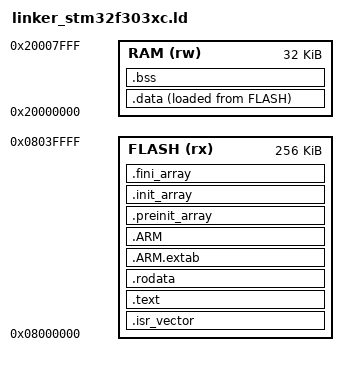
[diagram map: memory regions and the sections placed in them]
/**
 * linker_stm32f303xc.ld: Linker script for STM32F303xC (256K flash, 32K RAM).
 *
 * This is free software: you can redistribute it and/or modify
 * it under the terms of the GNU General Public License as published by
 * the Free Software Foundation, either version 3 of the License, or
 * (at your option) any later version.
 */

ENTRY(Reset_Handler)

MEMORY
{
    FLASH  (rx)  : ORIGIN = 0x08000000, LENGTH = 256K
    RAM    (rw)  : ORIGIN = 0x20000000, LENGTH = 32K
}

SECTIONS
{
    .isr_vector :
    {
        . = ALIGN(4);
        KEEP(*(.isr_vector))
        . = ALIGN(4);
    } > FLASH

    .text :
    {
        . = ALIGN(4);
        *(.text .text.*)
        *(.glue_7)
        *(.glue_7t)
        *(.gnu.linkonce.t.*)
        . = ALIGN(4);

        KEEP(*(.init))
        KEEP(*(.fini))

        . = ALIGN(4);
        _etext = .;
    } > FLASH

    .rodata :
    {
        . = ALIGN(4);
        *(.rodata .rodata.*)
        *(.gnu.linkonce.r.*)
        . = ALIGN(4);
    } > FLASH

    .ARM.extab : { *(.ARM.extab* .gnu.linkonce.armextab.*) } > FLASH
    .ARM : {
        __exidx_start = .;
        *(.ARM.exidx*)
        __exidx_end = .;
    } > FLASH

    .preinit_array :
    {
        PROVIDE_HIDDEN (__preinit_array_start = .);
        KEEP (*(SORT(.preinit_array.*)))
        KEEP (*(.preinit_array))
        PROVIDE_HIDDEN (__preinit_array_end = .);
    } > FLASH

    .init_array :
    {
        PROVIDE_HIDDEN (__init_array_start = .);
        KEEP (*(SORT(.init_array.*)))
        KEEP (*(.init_array))
        PROVIDE_HIDDEN (__init_array_end = .);
    } > FLASH

    .fini_array :
    {
        PROVIDE_HIDDEN (__fini_array_start = .);
        KEEP (*(SORT(.fini_array.*)))
        KEEP (*(.fini_array))
        PROVIDE_HIDDEN (__fini_array_end = .);
    } > FLASH

    _sidata = LOADADDR(.data);

    .data :
    {
        . = ALIGN(4);
        _sdata = .;
        *(.data .data.*)
        *(.gnu.linkonce.d.*)
        . = ALIGN(4);
        _edata = .;
    } > RAM AT > FLASH

    .bss (NOLOAD) :
    {
        . = ALIGN(4);
        _sbss = .;
        __bss_start__ = _sbss;
        *(.bss .bss.*)
        *(.gnu.linkonce.b.*)
        *(COMMON)
        . = ALIGN(4);
        _ebss = .;
        __bss_end__ = _ebss;
    } > RAM

    /* Heap starts after BSS, stack starts at top of RAM and grows down.
       All RAM between heap and stack is shared between them. */
    _end = _ebss;
    end = _ebss;
    _estack = ORIGIN(RAM) + LENGTH(RAM);

    /DISCARD/ :
    {
        libc.a (*)
        libm.a (*)
        libgcc.a (*)
    }
}
